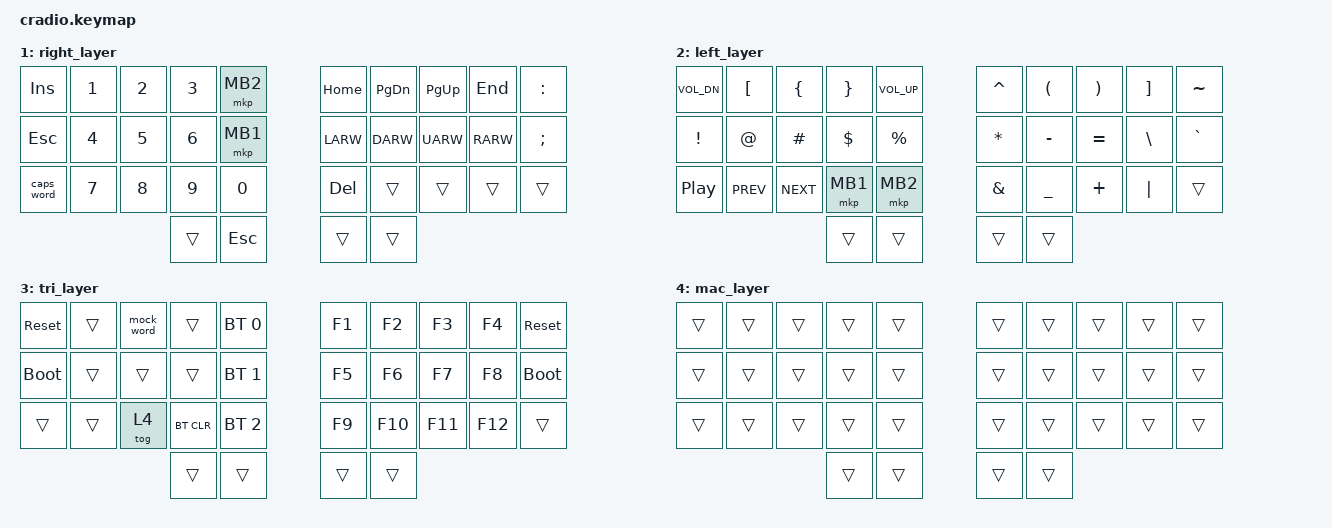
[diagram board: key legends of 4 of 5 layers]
// Copyright (c) 2022 The ZMK Contributors
// SPDX-License-Identifier: MIT

#include <behaviors.dtsi>
#include <dt-bindings/zmk/keys.h>
#include <dt-bindings/zmk/bt.h>
#include <dt-bindings/zmk/pointing.h>

// Home row mods macro
#define HRML(k1,k2,k3,k4) &ht LGUI k1  &ht LALT k2  &ht LCTRL k3  &ht LSHFT k4
#define HRMR(k1,k2,k3,k4) &ht RSHFT k1  &ht RCTRL k2  &ht RALT k3  &ht RGUI k4

// Combo macro. LAYERS is a space-separated layer list.
#define COMBO_ON(NAME, BINDINGS, KEYPOS, LAYERS) \
  combo_##NAME { \
    timeout-ms = <50>; \
    require-prior-idle-ms = <150>; \
    bindings = <BINDINGS>; \
    key-positions = <KEYPOS>; \
    layers = <LAYERS>; \
  };

// Default: active on the base layer and on the Mac layer, since combos are
// filtered by the *highest* active layer. Deliberately NOT written as a call
// to COMBO_ON -- that would let NAME expand (Z and Q are keys.h macros)
// before ## pastes it, yielding node names like combo_((0x07 << 16) | 0x1D).
#define COMBO(NAME, BINDINGS, KEYPOS) \
  combo_##NAME { \
    timeout-ms = <50>; \
    require-prior-idle-ms = <150>; \
    bindings = <BINDINGS>; \
    key-positions = <KEYPOS>; \
    layers = <0 4>; \
  };

/ {
      combos {
        compatible = "zmk,combos";
        COMBO(Z, &kp Z, 0 1)
        COMBO(Q, &kp Q, 1 2)
        COMBO(capsword, &caps_word, 1 3)

        COMBO(tmux, &kp LC(B), 11 13)
        COMBO(tmux2, &kp LC(B), 16 18)
        // Linux/Windows on the base layer, macOS on layer 4 (&tog 4).
        COMBO_ON(copy,  &kp LC(C), 21 22, 0)
        COMBO_ON(paste, &kp LC(V), 27 28, 0)
        COMBO_ON(undo,  &kp LC(Z), 26 27, 0)
        COMBO_ON(cut,   &kp LC(X), 20 21, 0)
        COMBO_ON(copy_mac,  &kp LG(C), 21 22, 4)
        COMBO_ON(paste_mac, &kp LG(V), 27 28, 4)
        COMBO_ON(undo_mac,  &kp LG(Z), 26 27, 4)
        COMBO_ON(cut_mac,   &kp LG(X), 20 21, 4)
        COMBO(backslash, &kp BSLH, 28 29)

        // Backspace nearly always follows a keystroke, so the shared
        // require-prior-idle-ms would block it right when it is needed.
        // Skips over O (27), which keeps it hard to roll into by accident.
        combo_bspc {
            timeout-ms = <50>;
            bindings = <&kp BSPC>;
            key-positions = <26 28>;
            layers = <0 4>;
        };

        COMBO(esckey, &kp ESC, 2 3)
        COMBO(esckey2, &kp ESC, 6 7)
        COMBO(tabkey, &kp TAB, 12 13)
        COMBO(tabkey2, &kp TAB, 16 17)
        COMBO(space, &kp SPACE, 22 23)
        COMBO(enter, &kp RET, 21 23)
        
        COMBO(one, &kp LC(N1), 0 10)
        COMBO(two, &kp LC(N2), 1 11)
        COMBO(three, &kp LC(N3), 2 12)
        COMBO(four, &kp LC(N4), 3 13)
        COMBO(five, &kp LC(N5), 4 14)
        COMBO(six, &kp LC(N6), 5 15)
        COMBO(seven, &kp LC(N7), 6 16)
        COMBO(eight, &kp LC(N8), 7 17)
        COMBO(nine, &kp LC(N9), 8 18)
        COMBO(zero, &kp LC(N0), 9 19)

        // COMBO(ctrlL, &kp LC(LEFT), 10 11)
        // COMBO(ctrlR, &kp LC(RIGHT), 11 12)
        // COMBO(ctrl1, &kp LC(N1), 4 5)
        // COMBO(ctrl2, &kp LC(N2), 14 15)
        // COMBO(ctrl3, &kp LC(N3), 24 25)
        // COMBO(ctrl4, &kp LC(N4), 6 7)
        // COMBO(ctrl5, &kp LC(N5), 16 17)
        // COMBO(ctrl6, &kp LC(N6), 26 27)

    };

    behaviors {
        ht: hold_tap {
            label = "hold_tap";
            compatible = "zmk,behavior-hold-tap";
            #binding-cells = <2>;
            flavor = "tap-preferred";
            tapping-term-ms = <220>;
            quick-tap-ms = <150>;
            global-quick-tap;
            bindings = <&kp>, <&kp>;
        };

        // SpongeBob random-caps mode. Toggle on, type, toggle off. SPACE is in
        // the continue-list so it mocks whole sentences; ends on enter/punct.
        mock_word: mock_word {
            compatible = "zmk,behavior-mock-word";
            #binding-cells = <0>;
            continue-list = <UNDERSCORE BACKSPACE DELETE MINUS SPACE>;
        };
    };

    conditional_layers {
        compatible = "zmk,conditional-layers";
        tri_layer {
            if-layers = <1 2>;
            then-layer = <3>;
        };
    };



    keymap {
        compatible = "zmk,keymap";
        default_layer {
            bindings = <
        //╭──────────┬──────────┬──────────┬──────────┬──────────╮   ╭──────────┬──────────┬──────────┬──────────┬──────────╮
        //│  X       │  W       │  M       │  G       │  J       │   │  \       │  .       │  /       │  '       │  `       │
            &kp X      &kp W      &kp M      &kp G      &kp J          &kp BSLH   &kp DOT    &kp FSLH   &kp SQT    &kp GRAVE
        //├──────────┼──────────┼──────────┼──────────┼──────────┤   ├──────────┼──────────┼──────────┼──────────┼──────────┤
        //│  S       │  C       │  N       │  T       │  K       │   │  ,       │  A       │  E       │  I       │   H      │
            HRML(S,     C,         N,         T)     &kp K          &kp COMMA  HRMR(A,         E,        I,          H)
        //├──────────┼──────────┼──────────┼──────────┼──────────┤   ├──────────┼──────────┼──────────┼──────────┼──────────┤
        //│  F       │  P       │  L       │  D       │  V       │   │  -       │  U       │  O       │    Y     │   B      │
            &kp F      &kp P      &kp L      &kp D      &kp V          &kp MINUS  &kp U      &kp O        &kp Y      &kp B
        //╰──────────┴──────────┴──────────┼──────────┼──────────┤   ├──────────┼──────────┼──────────┴──────────┴──────────╯
                                          &lt 2 C_VOL_DN &lt 2 R        &lt 1 SPACE &lt 1 C_VOL_UP
        //                                 ╰──────────┴──────────╯   ╰──────────┴──────────╯
            >;
        };

        right_layer {
            bindings = <
        //╭──────────┬──────────┬──────────┬──────────┬──────────╮   ╭──────────┬──────────┬──────────┬──────────┬──────────╮
        //│ INSERT   │  1       │  2       │  3       │          │   │ HOME     │ PAGE DN  │ PAGE UP  │ END      │  :       │
            &kp INS    &kp N1     &kp N2     &kp N3     &mkp MB2       &kp HOME   &kp PG_DN  &kp PG_UP  &kp END    &kp COLON
        //├──────────┼──────────┼──────────┼──────────┼──────────┤   ├──────────┼──────────┼──────────┼──────────┼──────────┤
        //│ ESC      │  4       │  5       │  6       │          │   │ LEFT     │ DOWN     │ UP       │ RIGHT    │  ;       │
            &kp ESC    &kp N4     &kp N5     &kp N6     &mkp MB1       &kp LARW   &kp DARW   &kp UARW   &kp RARW   &kp SEMI
        //├──────────┼──────────┼──────────┼──────────┼──────────┤   ├──────────┼──────────┼──────────┼──────────┼──────────┤
        //│ CAPS     │  7       │  8       │  9       │  0       │   │ DEL      │          │          │          │          │
           &caps_word  &kp N7     &kp N8     &kp N9     &kp N0         &kp DEL    &trans     &trans     &trans     &trans
        //╰──────────┴──────────┴──────────┼──────────┼──────────┤   ├──────────┼──────────┼──────────┴──────────┴──────────╯
                                             &trans     &kp ESC        &trans     &trans
        //                                 ╰──────────┴──────────╯   ╰──────────┴──────────╯
            >;
        };

        left_layer {
            bindings = <
        //╭──────────┬──────────┬──────────┬──────────┬──────────╮   ╭──────────┬──────────┬──────────┬──────────┬──────────╮
        //│ VOLDN    │  [       │  {       │  }       │  VOLUP   │   │  ^       │  (       │  )       │  ]       │  ~       │
            &kp C_VOL_DN &kp LBKT  &kp LBRC  &kp RBRC   &kp C_VOL_UP   &kp CARET  &kp LPAR   &kp RPAR   &kp RBKT   &kp TILDE
        //├──────────┼──────────┼──────────┼──────────┼──────────┤   ├──────────┼──────────┼──────────┼──────────┼──────────┤
        //│  !       │  @       │  #       │  $       │  %       │   │  *       │  -       │  =       │  \       │  `       │
            &kp EXCL   &kp AT     &kp HASH   &kp DLLR   &kp PRCNT      &kp ASTRK  &kp MINUS  &kp EQUAL  &kp BSLH   &kp GRAVE
        //├──────────┼──────────┼──────────┼──────────┼──────────┤   ├──────────┼──────────┼──────────┼──────────┼──────────┤
        //│          │          │          │          │          │   │  &       │  _       │  +       │  │       │          │
         &kp C_PP &kp C_PREV   &kp C_NEXT &mkp MB1      &mkp MB2       &kp AMPS   &kp UNDER  &kp PLUS   &kp PIPE   &trans
        //╰──────────┴──────────┴──────────┼──────────┼──────────┤   ├──────────┼──────────┼──────────┴──────────┴──────────╯
                                             &trans     &trans         &trans     &trans
        //                                 ╰──────────┴──────────╯   ╰──────────┴──────────╯
            >;
        };

        tri_layer {
            bindings = <
        //╭──────────┬──────────┬──────────┬──────────┬──────────╮   ╭──────────┬──────────┬──────────┬──────────┬──────────╮
        //│ RESET    │          │  MOCK    │          │PROFILE 0 │   │  F1      │  F2      │  F3      │  F4      │  RESET   │
           &sys_reset  &trans    &mock_word   &trans    &bt BT_SEL 0    &kp F1     &kp F2     &kp F3     &kp F4    &sys_reset
        //├──────────┼──────────┼──────────┼──────────┼──────────┤   ├──────────┼──────────┼──────────┼──────────┼──────────┤
        //│BOOTLOADER│          │          │          │PROFILE 1 │   │  F5      │  F6      │  F7      │  F8      │BOOTLOADER│
          &bootloader  &trans     &trans     &trans    &bt BT_SEL 1    &kp F5     &kp F6     &kp F7     &kp F8    &bootloader
        //├──────────┼──────────┼──────────┼──────────┼──────────┤   ├──────────┼──────────┼──────────┼──────────┼──────────┤
        //│          │          │ MAC MODE │ CLEAR BT │PROFILE 2 │   │  F9      │  F10     │  F11     │  F12     │          │
            &trans     &trans     &tog 4    &bt BT_CLR &bt BT_SEL 2    &kp F9     &kp F10    &kp F11    &kp F12    &trans
        //╰──────────┴──────────┴──────────┼──────────┼──────────┤   ├──────────┼──────────┼──────────┴──────────┴──────────╯
                                             &trans     &trans         &trans     &trans
        //                                 ╰──────────┴──────────╯   ╰──────────┴──────────╯
            >;
        };

        // Transparent throughout -- it exists purely to select the macOS
        // clipboard combos above. Toggle with &tog 4 on the tri-layer.
        mac_layer {
            bindings = <
            &trans     &trans     &trans     &trans     &trans         &trans     &trans     &trans     &trans     &trans
            &trans     &trans     &trans     &trans     &trans         &trans     &trans     &trans     &trans     &trans
            &trans     &trans     &trans     &trans     &trans         &trans     &trans     &trans     &trans     &trans
                                              &trans     &trans         &trans     &trans
            >;
        };
    };
};
